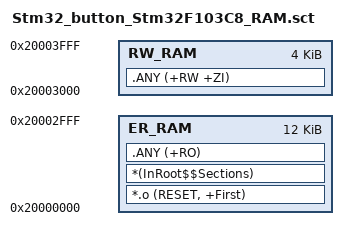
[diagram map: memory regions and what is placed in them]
; *************************************************************
; *** Scatter-Loading Description File generated by uVision ***
; *************************************************************

LR_RAM 0x20000000 0x00004000
{
  ER_RAM 0x20000000 0x00003000
  {
    *.o (RESET, +First)
    *(InRoot$$Sections)
    .ANY (+RO)
  }

  RW_RAM 0x20003000 0x00001000
  {
    .ANY (+RW +ZI)
  }
}
